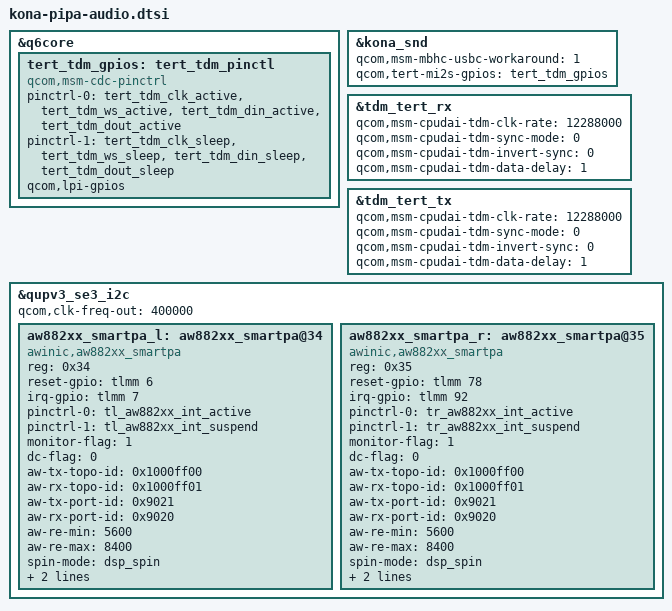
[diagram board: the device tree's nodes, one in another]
// SPDX-License-Identifier: GPL-2.0
/* Copyright (c) 2022, The Linux Foundation. All rights reserved.
 *
 * This program is free software; you can redistribute it and/or modify
 * it under the terms of the GNU General Public License version 2 and
 * only version 2 as published by the Free Software Foundation.
 *
 * This program is distributed in the hope that it will be useful,
 * but WITHOUT ANY WARRANTY; without even the implied warranty of
 * MERCHANTABILITY or FITNESS FOR A PARTICULAR PURPOSE.  See the
 * GNU General Public License for more details.
 */

&q6core {
	tert_tdm_gpios: tert_tdm_pinctl {
		compatible = "qcom,msm-cdc-pinctrl";
		pinctrl-names = "aud_active", "aud_sleep";
		pinctrl-0 = <&tert_tdm_clk_active &tert_tdm_ws_active
			&tert_tdm_din_active &tert_tdm_dout_active>;
		pinctrl-1 = <&tert_tdm_clk_sleep &tert_tdm_ws_sleep
			&tert_tdm_din_sleep &tert_tdm_dout_sleep>;
		qcom,lpi-gpios;
	};
};

&kona_snd {
	qcom,msm-mbhc-usbc-workaround = <1>;
	qcom,tert-mi2s-gpios = <&tert_tdm_gpios>;
};

&tdm_tert_rx {
	qcom,msm-cpudai-tdm-clk-rate = <12288000>;
	qcom,msm-cpudai-tdm-sync-mode = <0>;
	qcom,msm-cpudai-tdm-invert-sync = <0>;
	qcom,msm-cpudai-tdm-data-delay = <1>;
};

&tdm_tert_tx {
	qcom,msm-cpudai-tdm-clk-rate = <12288000>;
	qcom,msm-cpudai-tdm-sync-mode = <0>;
	qcom,msm-cpudai-tdm-invert-sync = <0>;
	qcom,msm-cpudai-tdm-data-delay = <1>;
};

&qupv3_se3_i2c {
	status = "ok";
	qcom,clk-freq-out = <400000>;

	/* Receiver */
	aw882xx_smartpa_l: aw882xx_smartpa@34 {
		compatible = "awinic,aw882xx_smartpa";
		reg = <0x34>;
		reset-gpio = <&tlmm 6 0>;
		irq-gpio = <&tlmm 7 0x2008>;
		pinctrl-names = "default", "sleep";
		pinctrl-0 = <&tl_aw882xx_int_active>;
		pinctrl-1 = <&tl_aw882xx_int_suspend>;
		monitor-flag = <1>;
		dc-flag = <0>;

		aw-tx-topo-id = <0x1000ff00>;
		aw-rx-topo-id = <0x1000ff01>;
		aw-tx-port-id = <0x9021>;
		aw-rx-port-id = <0x9020>;

		aw-re-min = <5600>;
		aw-re-max = <8400>;

		spin-mode = "dsp_spin";
		aw-cali-mode = "all";
		sound-channel = <0>; /*0:pri_l 1:pri_r 2:sec_l 3:sec_r*/
		status = "ok";
	};

	/* Speaker */
	aw882xx_smartpa_r: aw882xx_smartpa@35 {
		compatible = "awinic,aw882xx_smartpa";
		reg = <0x35>;
		reset-gpio = <&tlmm 78 0>;
		irq-gpio = <&tlmm 92 0x2008>;
		pinctrl-names = "default", "sleep";
		pinctrl-0 = <&tr_aw882xx_int_active>;
		pinctrl-1 = <&tr_aw882xx_int_suspend>;
		monitor-flag = <1>;
		dc-flag = <0>;

		aw-tx-topo-id = <0x1000ff00>;
		aw-rx-topo-id = <0x1000ff01>;
		aw-tx-port-id = <0x9021>;
		aw-rx-port-id = <0x9020>;

		aw-re-min = <5600>;
		aw-re-max = <8400>;

		spin-mode = "dsp_spin";
		aw-cali-mode = "all";
		sound-channel = <3>; /*0:pri_l 1:pri_r 2:sec_l 3:sec_r*/
		status = "ok";
	};
};
